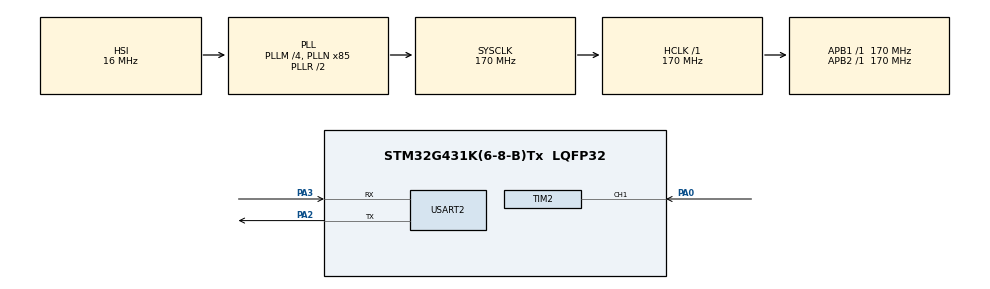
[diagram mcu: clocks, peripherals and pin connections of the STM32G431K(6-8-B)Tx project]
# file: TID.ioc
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Mcu.Family=STM32G4
Mcu.Name=STM32G431K(6-8-B)Tx
Mcu.Package=LQFP32
NVIC.PriorityGroup=NVIC_PRIORITYGROUP_4
NVIC.TIM2_IRQn=true\:0\:0\:false\:false\:true\:true\:true\:true
PA0.Signal=S_TIM2_CH1
PA2.Mode=Asynchronous
PA2.Signal=USART2_TX
PA3.Mode=Asynchronous
PA3.Signal=USART2_RX
ProjectManager.HeapSize=0x200
ProjectManager.StackSize=0x400
ProjectManager.TargetToolchain=STM32CubeIDE
RCC.ADC12Freq_Value=170000000
RCC.AHBFreq_Value=170000000
RCC.APB1Freq_Value=170000000
RCC.APB1TimFreq_Value=170000000
RCC.APB2Freq_Value=170000000
RCC.APB2TimFreq_Value=170000000
RCC.CortexFreq_Value=170000000
RCC.EXTERNAL_CLOCK_VALUE=12288000
RCC.HCLKFreq_Value=170000000
RCC.HSE_VALUE=8000000
RCC.HSI48_VALUE=48000000
RCC.HSI_VALUE=16000000
RCC.LSE_VALUE=32768
RCC.PLLM=RCC_PLLM_DIV4
RCC.PLLN=85
RCC.SYSCLKFreq_VALUE=170000000
RCC.SYSCLKSource=RCC_SYSCLKSOURCE_PLLCLK
RCC.USBFreq_Value=170000000
RCC.VCOOutputFreq_Value=340000000
SH.S_TIM2_CH1.0=TIM2_CH1,Input_Capture1_from_TI1
SH.S_TIM2_CH1.1=TIM2_CH1,TriggerSource_TI1FP1
TIM2.Channel-Input_Capture1_from_TI1=TIM_CHANNEL_1
TIM2.Channel-Input_Capture2_from_TI1_63=TIM_CHANNEL_2
TIM2.ICFilter_CH1=8
TIM2.ICPolarity_CH1=TIM_INPUTCHANNELPOLARITY_RISING
TIM2.ICPolarity_CH2=TIM_INPUTCHANNELPOLARITY_FALLING
TIM2.Prescaler=169
TIM2.TIM_MasterSlaveMode=TIM_MASTERSLAVEMODE_ENABLE
USART2.VirtualMode-Asynchronous=VM_ASYNC
VP_SYS_VS_DBSignals.Mode=DisableDeadBatterySignals
VP_TIM2_VS_ControllerModeReset.Mode=Reset Mode
VP_TIM2_VS_indirect_ch1.Mode=Input_Capture2_from_TI1_63
board=custom

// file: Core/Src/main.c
/* USER CODE BEGIN Header */
/**
  ******************************************************************************
  * @file           : main.c
  * @brief          : Main program body
  ******************************************************************************
  * @attention
  *
  * Copyright (c) 2026 STMicroelectronics.
  * All rights reserved.
  *
  * This software is licensed under terms that can be found in the LICENSE file
  * in the root directory of this software component.
  * If no LICENSE file comes with this software, it is provided AS-IS.
  *
  ******************************************************************************
  */
/* USER CODE END Header */
#include "main.h"

/* USER CODE BEGIN Includes */
#include "tacometro.h"
#include <stdio.h>
/* USER CODE END Includes */

TIM_HandleTypeDef htim2;

UART_HandleTypeDef huart2;

void SystemClock_Config(void);
static void MX_GPIO_Init(void);
static void MX_TIM2_Init(void);
static void MX_USART2_UART_Init(void);

int main(void)
{

  /* MCU Configuration--------------------------------------------------------*/

  /* Reset of all peripherals, Initializes the Flash interface and the Systick. */
  HAL_Init();

  /* Configure the system clock */
  SystemClock_Config();

  /* Initialize all configured peripherals */
  MX_GPIO_Init();
  MX_TIM2_Init();
  MX_USART2_UART_Init();
  /* USER CODE BEGIN 2 */
  /* USER CODE BEGIN 2 */
    Tacometro_Init(&htim2, TIM_CHANNEL_1);
    HAL_TIM_IC_Start_IT(&htim2, TIM_CHANNEL_1);
    HAL_TIM_IC_Start(&htim2, TIM_CHANNEL_2);
    printf("Tacometro STM32G431 - inicio\r\n");
    /* USER CODE END 2 */
  /* USER CODE END 2 */

  /* Infinite loop */
  /* USER CODE BEGIN WHILE */
  while (1)
  {
	  Tacometro_Update();

	  static uint32_t ultimoReporte = 0;
	  if (HAL_GetTick() - ultimoReporte >= 1000) {
	      ultimoReporte = HAL_GetTick();
	      printf("Frecuencia: %.1f Hz | RPM instant: %.1f | RPM filtrada: %.1f | Detenido: %d | RuidoFiltrado: %lu\r\n",
	          Tacometro_GetFrecuenciaHz(),
	          Tacometro_GetRPMInstantanea(),
	          Tacometro_GetRPMFiltrada(),
	          Tacometro_EstaDetenido(),
	          Tacometro_GetContadorRuidoFiltrado());
	  }

    /* USER CODE END WHILE */

  }
}

void SystemClock_Config(void)
{
  RCC_OscInitTypeDef RCC_OscInitStruct = {0};
  RCC_ClkInitTypeDef RCC_ClkInitStruct = {0};

  /** Configure the main internal regulator output voltage
  */
  HAL_PWREx_ControlVoltageScaling(PWR_REGULATOR_VOLTAGE_SCALE1_BOOST);

  /** Initializes the RCC Oscillators according to the specified parameters
  * in the RCC_OscInitTypeDef structure.
  */
  RCC_OscInitStruct.OscillatorType = RCC_OSCILLATORTYPE_HSI;
  RCC_OscInitStruct.HSIState = RCC_HSI_ON;
  RCC_OscInitStruct.HSICalibrationValue = RCC_HSICALIBRATION_DEFAULT;
  RCC_OscInitStruct.PLL.PLLState = RCC_PLL_ON;
  RCC_OscInitStruct.PLL.PLLSource = RCC_PLLSOURCE_HSI;
  RCC_OscInitStruct.PLL.PLLM = RCC_PLLM_DIV4;
  RCC_OscInitStruct.PLL.PLLN = 85;
  RCC_OscInitStruct.PLL.PLLP = RCC_PLLP_DIV2;
  RCC_OscInitStruct.PLL.PLLQ = RCC_PLLQ_DIV2;
  RCC_OscInitStruct.PLL.PLLR = RCC_PLLR_DIV2;
  if (HAL_RCC_OscConfig(&RCC_OscInitStruct) != HAL_OK)
  {
    Error_Handler();
  }

  /** Initializes the CPU, AHB and APB buses clocks
  */
  RCC_ClkInitStruct.ClockType = RCC_CLOCKTYPE_HCLK|RCC_CLOCKTYPE_SYSCLK
                              |RCC_CLOCKTYPE_PCLK1|RCC_CLOCKTYPE_PCLK2;
  RCC_ClkInitStruct.SYSCLKSource = RCC_SYSCLKSOURCE_PLLCLK;
  RCC_ClkInitStruct.AHBCLKDivider = RCC_SYSCLK_DIV1;
  RCC_ClkInitStruct.APB1CLKDivider = RCC_HCLK_DIV1;
  RCC_ClkInitStruct.APB2CLKDivider = RCC_HCLK_DIV1;

  if (HAL_RCC_ClockConfig(&RCC_ClkInitStruct, FLASH_LATENCY_4) != HAL_OK)
  {
    Error_Handler();
  }
}

static void MX_TIM2_Init(void)
{

  TIM_SlaveConfigTypeDef sSlaveConfig = {0};
  TIM_MasterConfigTypeDef sMasterConfig = {0};
  TIM_IC_InitTypeDef sConfigIC = {0};

  htim2.Instance = TIM2;
  htim2.Init.Prescaler = 169;
  htim2.Init.CounterMode = TIM_COUNTERMODE_UP;
  htim2.Init.Period = 4294967295;
  htim2.Init.ClockDivision = TIM_CLOCKDIVISION_DIV1;
  htim2.Init.AutoReloadPreload = TIM_AUTORELOAD_PRELOAD_DISABLE;
  if (HAL_TIM_Base_Init(&htim2) != HAL_OK)
  {
    Error_Handler();
  }
  if (HAL_TIM_IC_Init(&htim2) != HAL_OK)
  {
    Error_Handler();
  }
  sSlaveConfig.SlaveMode = TIM_SLAVEMODE_RESET;
  sSlaveConfig.InputTrigger = TIM_TS_TI1FP1;
  sSlaveConfig.TriggerPolarity = TIM_INPUTCHANNELPOLARITY_RISING;
  sSlaveConfig.TriggerFilter = 0;
  if (HAL_TIM_SlaveConfigSynchro(&htim2, &sSlaveConfig) != HAL_OK)
  {
    Error_Handler();
  }
  sMasterConfig.MasterOutputTrigger = TIM_TRGO_RESET;
  sMasterConfig.MasterSlaveMode = TIM_MASTERSLAVEMODE_ENABLE;
  if (HAL_TIMEx_MasterConfigSynchronization(&htim2, &sMasterConfig) != HAL_OK)
  {
    Error_Handler();
  }
  sConfigIC.ICPolarity = TIM_INPUTCHANNELPOLARITY_RISING;
  sConfigIC.ICSelection = TIM_ICSELECTION_DIRECTTI;
  sConfigIC.ICPrescaler = TIM_ICPSC_DIV1;
  sConfigIC.ICFilter = 8;
  if (HAL_TIM_IC_ConfigChannel(&htim2, &sConfigIC, TIM_CHANNEL_1) != HAL_OK)
  {
    Error_Handler();
  }
  sConfigIC.ICPolarity = TIM_INPUTCHANNELPOLARITY_FALLING;
  sConfigIC.ICSelection = TIM_ICSELECTION_INDIRECTTI;
  sConfigIC.ICFilter = 0;
  if (HAL_TIM_IC_ConfigChannel(&htim2, &sConfigIC, TIM_CHANNEL_2) != HAL_OK)
  {
    Error_Handler();
  }
  /* USER CODE BEGIN TIM2_Init 2 */
  sConfigIC.ICFilter = 8;
    if (HAL_TIM_IC_ConfigChannel(&htim2, &sConfigIC, TIM_CHANNEL_2) != HAL_OK)
    {
      Error_Handler();
    }
  /* USER CODE END TIM2_Init 2 */

}

static void MX_USART2_UART_Init(void)
{

  huart2.Instance = USART2;
  huart2.Init.BaudRate = 115200;
  huart2.Init.WordLength = UART_WORDLENGTH_8B;
  huart2.Init.StopBits = UART_STOPBITS_1;
  huart2.Init.Parity = UART_PARITY_NONE;
  huart2.Init.Mode = UART_MODE_TX_RX;
  huart2.Init.HwFlowCtl = UART_HWCONTROL_NONE;
  huart2.Init.OverSampling = UART_OVERSAMPLING_16;
  huart2.Init.OneBitSampling = UART_ONE_BIT_SAMPLE_DISABLE;
  huart2.Init.ClockPrescaler = UART_PRESCALER_DIV1;
  huart2.AdvancedInit.AdvFeatureInit = UART_ADVFEATURE_NO_INIT;
  if (HAL_UART_Init(&huart2) != HAL_OK)
  {
    Error_Handler();
  }
  if (HAL_UARTEx_SetTxFifoThreshold(&huart2, UART_TXFIFO_THRESHOLD_1_8) != HAL_OK)
  {
    Error_Handler();
  }
  if (HAL_UARTEx_SetRxFifoThreshold(&huart2, UART_RXFIFO_THRESHOLD_1_8) != HAL_OK)
  {
    Error_Handler();
  }
  if (HAL_UARTEx_DisableFifoMode(&huart2) != HAL_OK)
  {
    Error_Handler();
  }

}

static void MX_GPIO_Init(void)
{

  /* GPIO Ports Clock Enable */
  __HAL_RCC_GPIOA_CLK_ENABLE();

}

/* USER CODE BEGIN 4 */
void HAL_TIM_IC_CaptureCallback(TIM_HandleTypeDef *htim)
{
    Tacometro_CaptureCallback(htim);
}

#ifdef __GNUC__
int __io_putchar(int ch)
{
    HAL_UART_Transmit(&huart2, (uint8_t*)&ch, 1, HAL_MAX_DELAY);
    return ch;
}
#endif
/* USER CODE END 4 */

void Error_Handler(void)
{
  __disable_irq();
  while (1)
  {
  }
}
